# I3C0_MMR_MMRVBP register map
Vendor: Texas Instruments
Peripheral module from a debugger description file (folder J7VCL).
Registers are 32-bit, read-only, reset 0x68A06100 unless marked. A register's access mark holds for its fields unless they carry their own. Offsets are as the file gives them; lines under a group give offsets from that group; [hi:lo] are bit positions; {n}, {i} and the like mark numbered series; 'fields as' and 'values as' point back to an identical list; <NAME> marks a mode.

## I3C0_MMR_MMRVBP
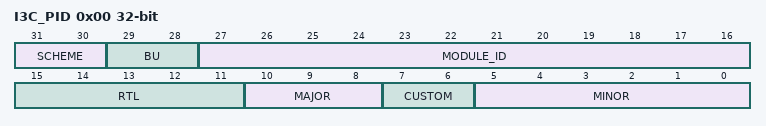
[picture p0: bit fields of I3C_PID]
0x00 I3C_PID — Return to the . The Revision Register contains the major and minor revisions for the module.
  [31:30] SCHEME
  [29:28] BU — Business Unit:
  [27:16] MODULE_ID
  [15:11] RTL — RTL revision.
  [10:8] MAJOR — Major revision
  [7:6] CUSTOM
  [5:0] MINOR — Minor revision
